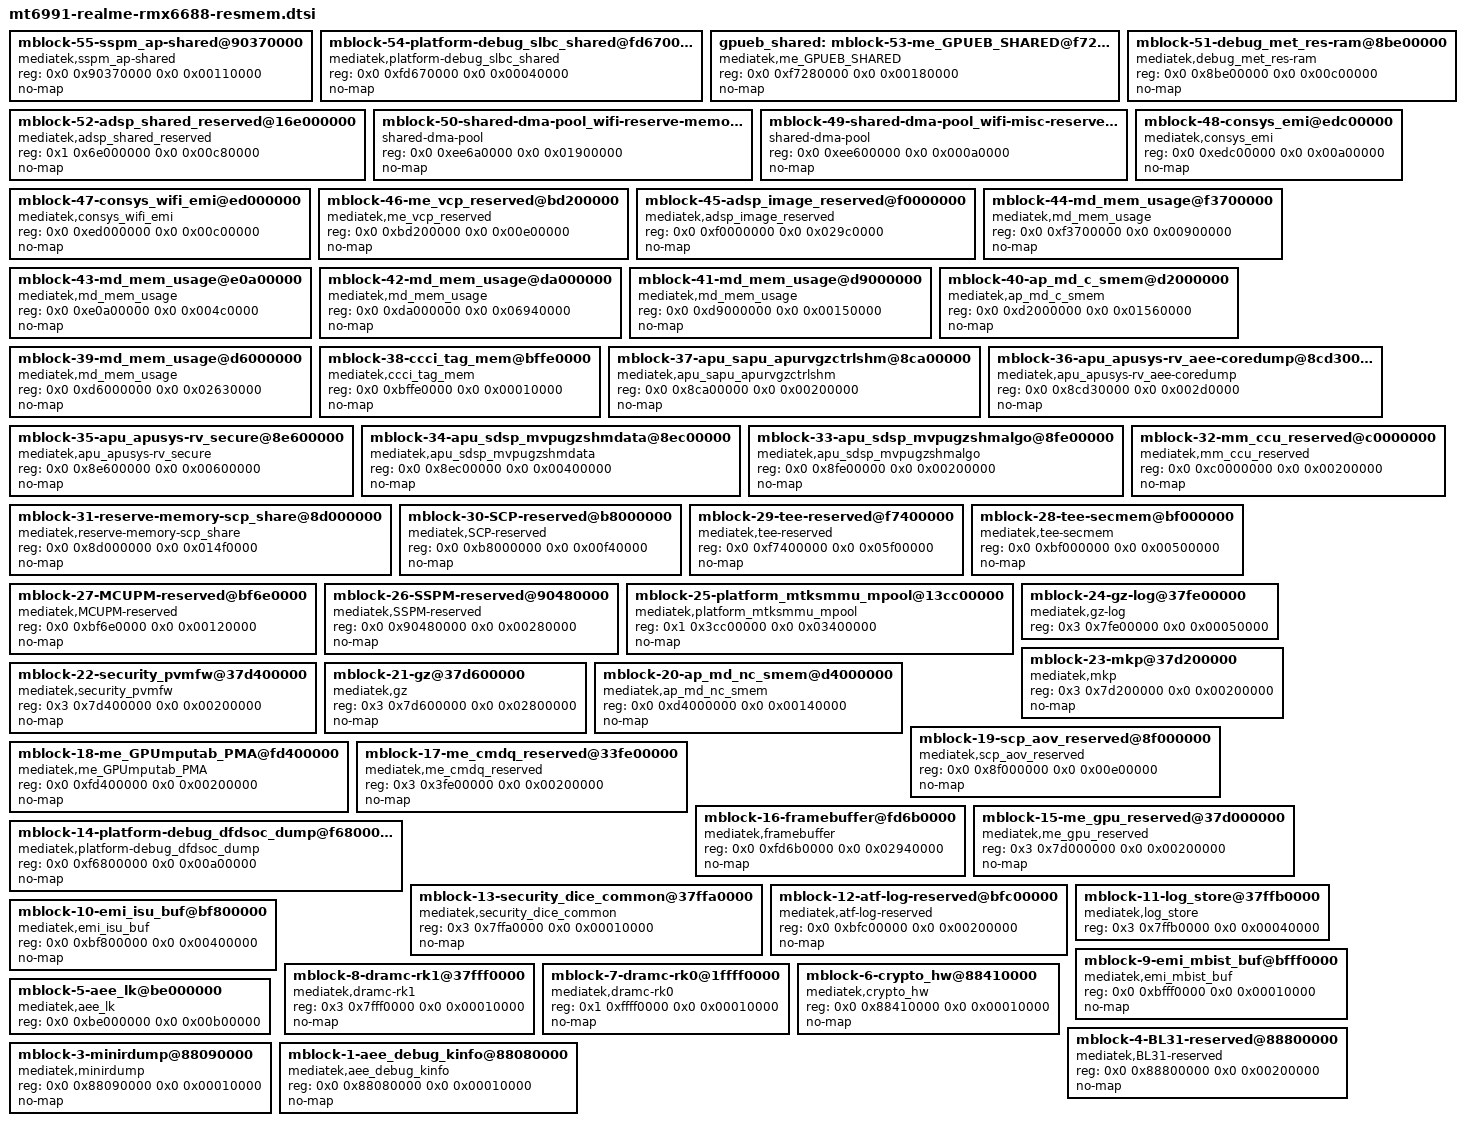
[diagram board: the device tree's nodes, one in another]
// SPDX-License-Identifier: (GPL-2.0 OR MIT)
/*
 * Fixed memory reservations for realme GT7 (RMX6688), MT6991.
 *
 * GENERATED by gen_resmem.py from the vendor /sys/firmware/fdt -- do not
 * edit by hand.  Included from inside the reserved-memory node.
 */

	mblock-55-sspm_ap-shared@90370000 {
		compatible = "mediatek,sspm_ap-shared";
		reg = <0x0 0x90370000 0x0 0x00110000>;
		no-map;
	};

	mblock-54-platform-debug_slbc_shared@fd670000 {
		compatible = "mediatek,platform-debug_slbc_shared";
		reg = <0x0 0xfd670000 0x0 0x00040000>;
		no-map;
	};

	gpueb_shared: mblock-53-me_GPUEB_SHARED@f7280000 {
		compatible = "mediatek,me_GPUEB_SHARED";
		reg = <0x0 0xf7280000 0x0 0x00180000>;
		no-map;
	};

	mblock-52-adsp_shared_reserved@16e000000 {
		compatible = "mediatek,adsp_shared_reserved";
		reg = <0x1 0x6e000000 0x0 0x00c80000>;
		no-map;
	};

	mblock-51-debug_met_res-ram@8be00000 {
		compatible = "mediatek,debug_met_res-ram";
		reg = <0x0 0x8be00000 0x0 0x00c00000>;
		no-map;
	};

	mblock-50-shared-dma-pool_wifi-reserve-memory_dma@ee6a0000 {
		compatible = "shared-dma-pool";
		reg = <0x0 0xee6a0000 0x0 0x01900000>;
		no-map;
	};

	mblock-49-shared-dma-pool_wifi-misc-reserve-memory_dma@ee600000 {
		compatible = "shared-dma-pool";
		reg = <0x0 0xee600000 0x0 0x000a0000>;
		no-map;
	};

	mblock-48-consys_emi@edc00000 {
		compatible = "mediatek,consys_emi";
		reg = <0x0 0xedc00000 0x0 0x00a00000>;
		no-map;
	};

	mblock-47-consys_wifi_emi@ed000000 {
		compatible = "mediatek,consys_wifi_emi";
		reg = <0x0 0xed000000 0x0 0x00c00000>;
		no-map;
	};

	mblock-46-me_vcp_reserved@bd200000 {
		compatible = "mediatek,me_vcp_reserved";
		reg = <0x0 0xbd200000 0x0 0x00e00000>;
		no-map;
	};

	mblock-45-adsp_image_reserved@f0000000 {
		compatible = "mediatek,adsp_image_reserved";
		reg = <0x0 0xf0000000 0x0 0x029c0000>;
		no-map;
	};

	mblock-44-md_mem_usage@f3700000 {
		compatible = "mediatek,md_mem_usage";
		reg = <0x0 0xf3700000 0x0 0x00900000>;
		no-map;
	};

	mblock-43-md_mem_usage@e0a00000 {
		compatible = "mediatek,md_mem_usage";
		reg = <0x0 0xe0a00000 0x0 0x004c0000>;
		no-map;
	};

	mblock-42-md_mem_usage@da000000 {
		compatible = "mediatek,md_mem_usage";
		reg = <0x0 0xda000000 0x0 0x06940000>;
		no-map;
	};

	mblock-41-md_mem_usage@d9000000 {
		compatible = "mediatek,md_mem_usage";
		reg = <0x0 0xd9000000 0x0 0x00150000>;
		no-map;
	};

	mblock-40-ap_md_c_smem@d2000000 {
		compatible = "mediatek,ap_md_c_smem";
		reg = <0x0 0xd2000000 0x0 0x01560000>;
		no-map;
	};

	mblock-39-md_mem_usage@d6000000 {
		compatible = "mediatek,md_mem_usage";
		reg = <0x0 0xd6000000 0x0 0x02630000>;
		no-map;
	};

	mblock-38-ccci_tag_mem@bffe0000 {
		compatible = "mediatek,ccci_tag_mem";
		reg = <0x0 0xbffe0000 0x0 0x00010000>;
		no-map;
	};

	mblock-37-apu_sapu_apurvgzctrlshm@8ca00000 {
		compatible = "mediatek,apu_sapu_apurvgzctrlshm";
		reg = <0x0 0x8ca00000 0x0 0x00200000>;
		no-map;
	};

	mblock-36-apu_apusys-rv_aee-coredump@8cd30000 {
		compatible = "mediatek,apu_apusys-rv_aee-coredump";
		reg = <0x0 0x8cd30000 0x0 0x002d0000>;
		no-map;
	};

	mblock-35-apu_apusys-rv_secure@8e600000 {
		compatible = "mediatek,apu_apusys-rv_secure";
		reg = <0x0 0x8e600000 0x0 0x00600000>;
		no-map;
	};

	mblock-34-apu_sdsp_mvpugzshmdata@8ec00000 {
		compatible = "mediatek,apu_sdsp_mvpugzshmdata";
		reg = <0x0 0x8ec00000 0x0 0x00400000>;
		no-map;
	};

	mblock-33-apu_sdsp_mvpugzshmalgo@8fe00000 {
		compatible = "mediatek,apu_sdsp_mvpugzshmalgo";
		reg = <0x0 0x8fe00000 0x0 0x00200000>;
		no-map;
	};

	mblock-32-mm_ccu_reserved@c0000000 {
		compatible = "mediatek,mm_ccu_reserved";
		reg = <0x0 0xc0000000 0x0 0x00200000>;
		no-map;
	};

	mblock-31-reserve-memory-scp_share@8d000000 {
		compatible = "mediatek,reserve-memory-scp_share";
		reg = <0x0 0x8d000000 0x0 0x014f0000>;
		no-map;
	};

	mblock-30-SCP-reserved@b8000000 {
		compatible = "mediatek,SCP-reserved";
		reg = <0x0 0xb8000000 0x0 0x00f40000>;
		no-map;
	};

	mblock-29-tee-reserved@f7400000 {
		compatible = "mediatek,tee-reserved";
		reg = <0x0 0xf7400000 0x0 0x05f00000>;
		no-map;
	};

	mblock-28-tee-secmem@bf000000 {
		compatible = "mediatek,tee-secmem";
		reg = <0x0 0xbf000000 0x0 0x00500000>;
		no-map;
	};

	mblock-27-MCUPM-reserved@bf6e0000 {
		compatible = "mediatek,MCUPM-reserved";
		reg = <0x0 0xbf6e0000 0x0 0x00120000>;
		no-map;
	};

	mblock-26-SSPM-reserved@90480000 {
		compatible = "mediatek,SSPM-reserved";
		reg = <0x0 0x90480000 0x0 0x00280000>;
		no-map;
	};

	mblock-25-platform_mtksmmu_mpool@13cc00000 {
		compatible = "mediatek,platform_mtksmmu_mpool";
		reg = <0x1 0x3cc00000 0x0 0x03400000>;
		no-map;
	};

	mblock-24-gz-log@37fe00000 {
		compatible = "mediatek,gz-log";
		reg = <0x3 0x7fe00000 0x0 0x00050000>;
	};

	mblock-23-mkp@37d200000 {
		compatible = "mediatek,mkp";
		reg = <0x3 0x7d200000 0x0 0x00200000>;
		no-map;
	};

	mblock-22-security_pvmfw@37d400000 {
		compatible = "mediatek,security_pvmfw";
		reg = <0x3 0x7d400000 0x0 0x00200000>;
		no-map;
	};

	mblock-21-gz@37d600000 {
		compatible = "mediatek,gz";
		reg = <0x3 0x7d600000 0x0 0x02800000>;
		no-map;
	};

	mblock-20-ap_md_nc_smem@d4000000 {
		compatible = "mediatek,ap_md_nc_smem";
		reg = <0x0 0xd4000000 0x0 0x00140000>;
		no-map;
	};

	mblock-19-scp_aov_reserved@8f000000 {
		compatible = "mediatek,scp_aov_reserved";
		reg = <0x0 0x8f000000 0x0 0x00e00000>;
		no-map;
	};

	mblock-18-me_GPUmputab_PMA@fd400000 {
		compatible = "mediatek,me_GPUmputab_PMA";
		reg = <0x0 0xfd400000 0x0 0x00200000>;
		no-map;
	};

	mblock-17-me_cmdq_reserved@33fe00000 {
		compatible = "mediatek,me_cmdq_reserved";
		reg = <0x3 0x3fe00000 0x0 0x00200000>;
		no-map;
	};

	mblock-16-framebuffer@fd6b0000 {
		compatible = "mediatek,framebuffer";
		reg = <0x0 0xfd6b0000 0x0 0x02940000>;
		no-map;
	};

	mblock-15-me_gpu_reserved@37d000000 {
		compatible = "mediatek,me_gpu_reserved";
		reg = <0x3 0x7d000000 0x0 0x00200000>;
		no-map;
	};

	mblock-14-platform-debug_dfdsoc_dump@f6800000 {
		compatible = "mediatek,platform-debug_dfdsoc_dump";
		reg = <0x0 0xf6800000 0x0 0x00a00000>;
		no-map;
	};

	mblock-13-security_dice_common@37ffa0000 {
		compatible = "mediatek,security_dice_common";
		reg = <0x3 0x7ffa0000 0x0 0x00010000>;
		no-map;
	};

	mblock-12-atf-log-reserved@bfc00000 {
		compatible = "mediatek,atf-log-reserved";
		reg = <0x0 0xbfc00000 0x0 0x00200000>;
		no-map;
	};

	mblock-11-log_store@37ffb0000 {
		compatible = "mediatek,log_store";
		reg = <0x3 0x7ffb0000 0x0 0x00040000>;
	};

	mblock-10-emi_isu_buf@bf800000 {
		compatible = "mediatek,emi_isu_buf";
		reg = <0x0 0xbf800000 0x0 0x00400000>;
		no-map;
	};

	mblock-9-emi_mbist_buf@bfff0000 {
		compatible = "mediatek,emi_mbist_buf";
		reg = <0x0 0xbfff0000 0x0 0x00010000>;
		no-map;
	};

	mblock-8-dramc-rk1@37fff0000 {
		compatible = "mediatek,dramc-rk1";
		reg = <0x3 0x7fff0000 0x0 0x00010000>;
		no-map;
	};

	mblock-7-dramc-rk0@1ffff0000 {
		compatible = "mediatek,dramc-rk0";
		reg = <0x1 0xffff0000 0x0 0x00010000>;
		no-map;
	};

	mblock-6-crypto_hw@88410000 {
		compatible = "mediatek,crypto_hw";
		reg = <0x0 0x88410000 0x0 0x00010000>;
		no-map;
	};

	mblock-5-aee_lk@be000000 {
		compatible = "mediatek,aee_lk";
		reg = <0x0 0xbe000000 0x0 0x00b00000>;
	};

	mblock-4-BL31-reserved@88800000 {
		compatible = "mediatek,BL31-reserved";
		reg = <0x0 0x88800000 0x0 0x00200000>;
		no-map;
	};

	mblock-3-minirdump@88090000 {
		compatible = "mediatek,minirdump";
		reg = <0x0 0x88090000 0x0 0x00010000>;
		no-map;
	};

	mblock-1-aee_debug_kinfo@88080000 {
		compatible = "mediatek,aee_debug_kinfo";
		reg = <0x0 0x88080000 0x0 0x00010000>;
		no-map;
	};

